# R7FA8D1BH register map
Vendor: Renesas; Series: RA8; File version: 1.2
CPU: CM85 r0p0, little endian, MPU, FPU, VTOR, 4 interrupt priority bits
Registers are 32-bit, read-write, reset 0x0 unless marked. A register's access mark holds for its fields unless they carry their own. Offsets are from the block's base; [hi:lo] are bit positions; {n}, {i} and the like mark numbered series; 'fields as' and 'values as' point back to an identical list.

## BUS — BUS Control
Base 0x40003000
Same registers: BUS_NS 0x50003000
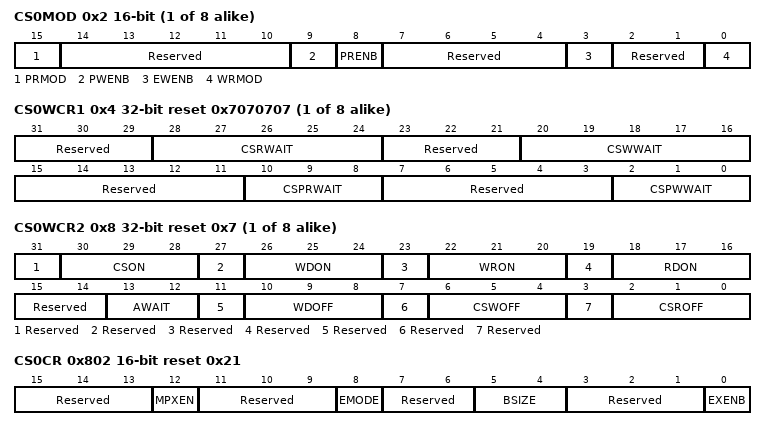
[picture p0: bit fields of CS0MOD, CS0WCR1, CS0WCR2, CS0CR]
{0x2+0x10*i} CS{i}MOD (i=0..7) 16-bit — CS{i} Mode Register
  [15] PRMOD — Page Read Access Mode Select
    0=Normal access compatible mode; 1=External data read continuous assertion mode
  [14:10] Reserved — These bits are read as 00000. The write value should be 00000.
  [9] PWENB — Page Write Access Enable
    0=Disabled; 1=Enabled
  [8] PRENB — Page Read Access Enable
    0=Disabled; 1=Enabled
  [7:4] Reserved — These bits are read as 0000. The write value should be 0000.
  [3] EWENB — External Wait Enable
    0=Disabled; 1=Enabled
  [2:1] Reserved — These bits are read as 00. The write value should be 00.
  [0] WRMOD — Write Access Mode Select
    0=Byte strobe mode; 1=Single write strobe mode
{0x4+0x10*i} CS{i}WCR1 (i=0..7) reset 0x7070707 — CS{i} Wait Control Register 1
  [31:29] Reserved — These bits are read as 000. The write value should be 000.
  [28:24] CSRWAIT — Normal Read Cycle Wait Select
    0=No wait is inserted; other=others (Wait with a length of CSRWAIT clock cycle is inserted.)
  [23:21] Reserved — These bits are read as 000. The write value should be 000.
  [20:16] CSWWAIT — Normal Write Cycle Wait Select
    0=No wait is inserted; other=others (Wait with a length of CSWWAIT clock cycle is inserted.)
  [15:11] Reserved — These bits are read as 00000. The write value should be 00000.
  [10:8] CSPRWAIT — Page Read Cycle Wait SelectNOTE: The CSPRWAIT value is valid only when the PRENB bit in CSnMOD is set to 1.
    0=No wait is inserted; other=others (Wait with a length of CSPRWAIT clock cycle is inserted.)
  [7:3] Reserved — These bits are read as 00000. The write value should be 00000.
  [2:0] CSPWWAIT — Page Write Cycle Wait SelectNOTE: The CSPWWAIT value is valid only when the PWENB bit in CSnMOD is set to 1.
    0=No wait is inserted; other=others (Wait with a length of CSPWWAIT clock cycle is inserted.)
{0x8+0x10*i} CS{i}WCR2 (i=0..7) reset 0x7 — CS{i} Wait Control Register 2
  [31] Reserved — This bit is read as 0. The write value should be 0.
  [30:28] CSON — CS Assert Wait Select
    0=No wait is inserted; other=others (Wait with a length of CSON clock cycle is inserted.)
  [27] Reserved — This bit is read as 0. The write value should be 0.
  [26:24] WDON — Write Data Output Wait Select
    0=No wait is inserted; other=others (Wait with a length of WDON clock cycle is inserted.)
  [23] Reserved — This bit is read as 0. The write value should be 0.
  [22:20] WRON — WR Assert Wait Select
    0=No wait is inserted; other=others (Wait with a length of WRON clock cycle is inserted.)
  [19] Reserved — This bit is read as 0. The write value should be 0.
  [18:16] RDON — RD Assert Wait Select
    0=No wait is inserted; other=others (Wait with a length of RDON clock cycle is inserted.)
  [15:14] Reserved — These bits are read as 00. The write value should be 00.
  [13:12] AWAIT — Address Cycle Wait Select
    0=No wait is inserted; other=others (Wait with a length of AWAIT clock cycle is inserted.)
  [11] Reserved — This bit is read as 0. The write value should be 0.
  [10:8] WDOFF — Write Data Output Extension Cycle Select
    0=No wait is inserted; other=others (Wait with a length of WDOFF clock cycle is inserted.)
  [7] Reserved — This bit is read as 0. The write value should be 0.
  [6:4] CSWOFF — Write Access CS Extension Cycle Select
    0=No wait is inserted; other=others (Wait with a length of CSWOFF clock cycle is inserted.)
  [3] Reserved — This bit is read as 0. The write value should be 0.
  [2:0] CSROFF — Read Access CS Extension Cycle Select
    0=No wait is inserted; other=others (Wait with a length of CSROFF clock cycle is inserted.)
0x802 CS0CR 16-bit reset 0x21 — CS0 Control Register
  [15:13] Reserved — These bits are read as 000. The write value should be 000.
  [12] MPXEN — Address/Data Multiplexed I/O Interface Select
    0=Separate bus interface is selected for area n; 1=Address/data multiplexed I/O interface is selected for area n. (n = 0 to 7)
  [11:9] Reserved — These bits are read as 000. The write value should be 000.
  [8] EMODE — Endian Mode
    0=Little endian; 1=Big endian
  [7:6] Reserved — These bits are read as 00. The write value should be 00.
  [5:4] BSIZE — External Bus Width Select
    0=16-bit bus space; 1=32-bit bus space; 2=8-bit bus space; other=others (Setting prohibited.)
  [3:1] Reserved — These bits are read as 000. The write value should be 000.
  [0] EXENB — Operation Enable
    0=Disable operation; 1=Enable operation
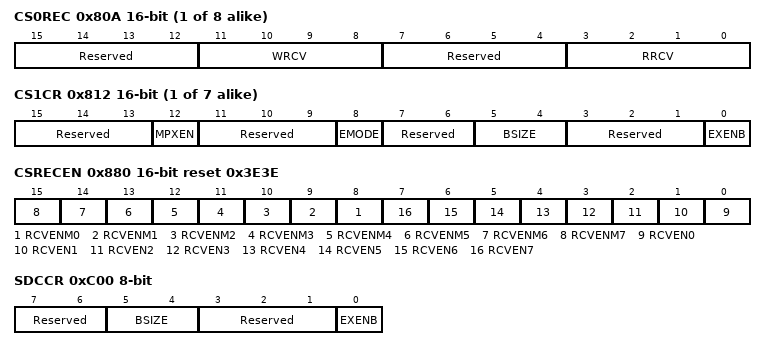
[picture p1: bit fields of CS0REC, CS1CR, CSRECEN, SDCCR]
{0x80A+0x10*i} CS{i}REC (i=0..7) 16-bit — CS{i} Recovery Cycle Register
  [15:12] Reserved — These bits are read as 0000. The write value should be 0000.
  [11:8] WRCV — Write Recovery
    0=No recovery cycle is inserted; other=others (WRCV recovery cycle is inserted.)
  [7:4] Reserved — These bits are read as 0000. The write value should be 0000.
  [3:0] RRCV — Read Recovery
    0=No recovery cycle is inserted; other=others (RRCV recovery cycle is inserted.)
{0x802+0x10*i} CS{i}CR (i=1..7) 16-bit — CS{i} Control Register
  fields as CS0CR
0x880 CSRECEN 16-bit reset 0x3E3E — CS Recovery Cycle Insertion Enable Register
  [all] fields
    0=Disabled; 1=Enabled
  [n+8] RCVENM{n} (n=0..7) — Multiplexed Bus Recovery Cycle Insertion Enable {n}
  [n] RCVEN{n} (n=0..7) — Separate Bus Recovery Cycle Insertion Enable {n}
0xC00 SDCCR 8-bit — SDC Control Register
  [7:6] Reserved — These bits are read as 00. The write value should be 00.
  [5:4] BSIZE — SDRAM Bus Width Select
    values as CS0CR.BSIZE
  [3:1] Reserved — These bits are read as 000. The write value should be 000.
  [0] EXENB — Operation Enable
    0=Disable; 1=Enable
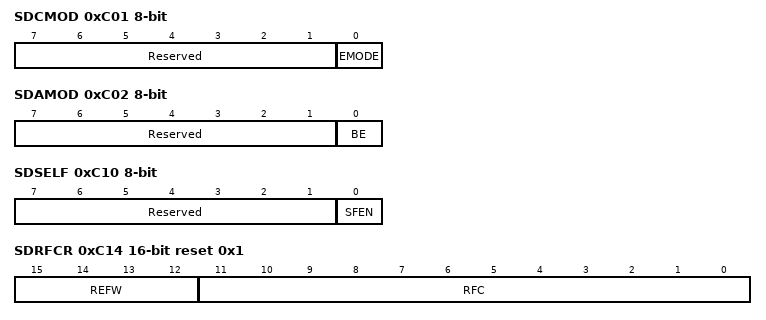
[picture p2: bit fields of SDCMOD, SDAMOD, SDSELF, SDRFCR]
0xC01 SDCMOD 8-bit — SDC Mode Register
  [7:1] Reserved — These bits are read as 0000000. The write value should be 0000000.
  [0] EMODE — Endian Mode
    0=Endian order of SDRAM address space is the same as the endian order of the operating mode; 1=Endian order of SDRAM address space is not the endian order of the operating mode
0xC02 SDAMOD 8-bit — SDRAM Access Mode Register
  [7:1] Reserved — These bits are read as 0000000. The write value should be 0000000.
  [0] BE — Continuous Access Enable
    0=Continuous access is disabled; 1=Continuous access is enabled
0xC10 SDSELF 8-bit — SDRAM Self-Refresh Control Register
  [7:1] Reserved — These bits are read as 0000000. The write value should be 0000000.
  [0] SFEN — SDRAM Self-Refresh Enable
    0=Disable; 1=Enable
0xC14 SDRFCR 16-bit reset 0x1 — SDRAM Refresh Control Register
  [15:12] REFW — Auto-Refresh Cycle/ Self-Refresh Clearing Cycle Count Setting. ( REFW+1 Cycles )
  [11:0] RFC — Auto-Refresh Request Interval Setting
    0=Setting prohibited; other=others (RFC+1 cycles inserted)
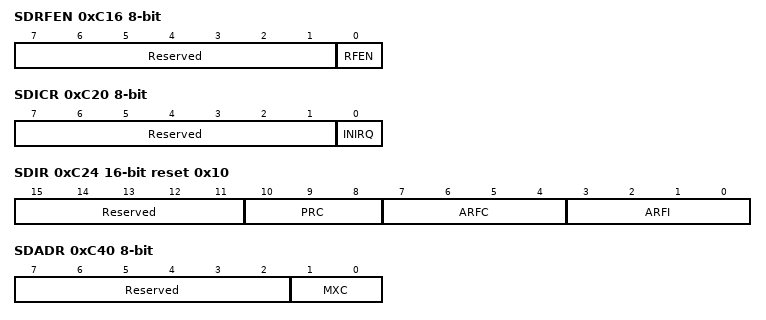
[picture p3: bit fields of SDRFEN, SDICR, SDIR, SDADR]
0xC16 SDRFEN 8-bit — SDRAM Auto-Refresh Control Register
  [7:1] Reserved — These bits are read as 0000000. The write value should be 0000000.
  [0] RFEN — Auto-Refresh Operation Enable
    0=Disable; 1=Enable
0xC20 SDICR 8-bit — SDRAM Initialization Sequence Control Register
  [7:1] Reserved — These bits are read as 0000000. The write value should be 0000000.
  [0] INIRQ — Initialization Sequence Start
    0=Invalid; 1=Initialization sequence starts
0xC24 SDIR 16-bit reset 0x10 — SDRAM Initialization Register
  [15:11] Reserved — These bits are read as 00000. The write value should be 00000.
  [10:8] PRC — Initialization Precharge Cycle Count ( PRF+3 cycles )
  [7:4] ARFC — Initialization Auto-Refresh Count
    0=Setting prohibited; other=others (ARFC+1 times)
  [3:0] ARFI — Initialization Auto-Refresh Interval ( PRF+3 cycles )
0xC40 SDADR 8-bit — SDRAM Address Register
  [7:2] Reserved — These bits are read as 000000. The write value should be 000000.
  [1:0] MXC — Address Multiplex Select
    {v}={v+8}-bit shift (v=0..3)
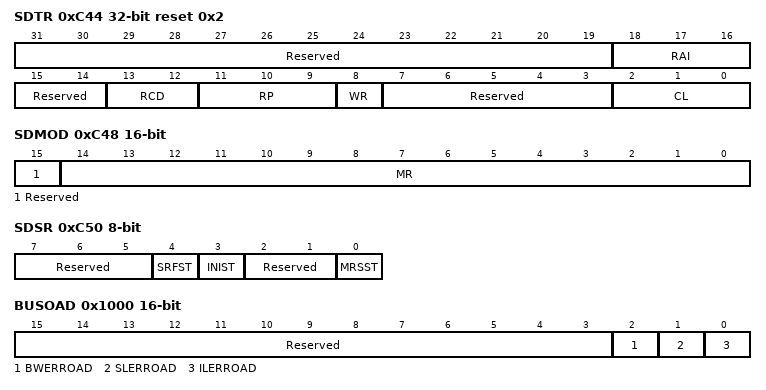
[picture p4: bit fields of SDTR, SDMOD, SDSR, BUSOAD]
0xC44 SDTR reset 0x2 — SDRAM Timing Register
  [31:19] Reserved — These bits are read as 0000000000000. The write value should be 0000000000000.
  [18:16] RAI — Row Active Interval
    0=1 cycle; {v}={v+1} cycles (v=1..6); 7=Setting prohibited
  [15:14] Reserved — These bits are read as 00. The write value should be 00.
  [13:12] RCD — Row Column Latency ( RCD+1 cycles )
  [11:9] RP — Row Precharge Interval ( RP+1 cycles )
  [8] WR — Write Recovery Interval
    0=1 cycle; 1=2 cycles
  [7:3] Reserved — These bits are read as 00000. The write value should be 00000.
  [2:0] CL — SDRAMC Column Latency
    1=1 cycle; 2=2 cycles; 3=3 cycles; other=others (Setting prohibited)
0xC48 SDMOD 16-bit — SDRAM Mode Register
  [15] Reserved — This bit is read as 0. The write value should be 0.
  [14:0] MR — Mode Register SettingWriting to these bits: Mode register set command is issued.
0xC50 SDSR 8-bit ro — SDRAM Status Register
  [7:5] Reserved — These bits are read as 000.
  [4] SRFST — Self-Refresh Transition/Recovery Status
    0=Transition/recovery not in progress; 1=Transition/recovery in progress
  [3] INIST — Initialization Status
    0=Initialization sequence not in progress; 1=Initialization sequence in progress
  [2:1] Reserved — These bits are read as 00.
  [0] MRSST — Mode Register Setting Status
    0=Mode register setting not in progress; 1=Mode register setting in progress
0x1000 BUSOAD 16-bit (reset mask 0x7) — BUS_Operation_After_Detection Register
  [15:3] Reserved — These bits are read as 0000000000000. The write value should be 0000000000000.
  [2] BWERROAD — Bufferable write error operation after detection
    0=NMI; 1=Reset
  [1] SLERROAD — Slave bus error operation after detection
    0=Only error response is returned; 1=Reset; 0=NMI; 1=Reset
  [0] ILERROAD — Illegal address access error operation after detection
    0=Only error response is returned; 1=Reset; 0=NMI; 1=Reset
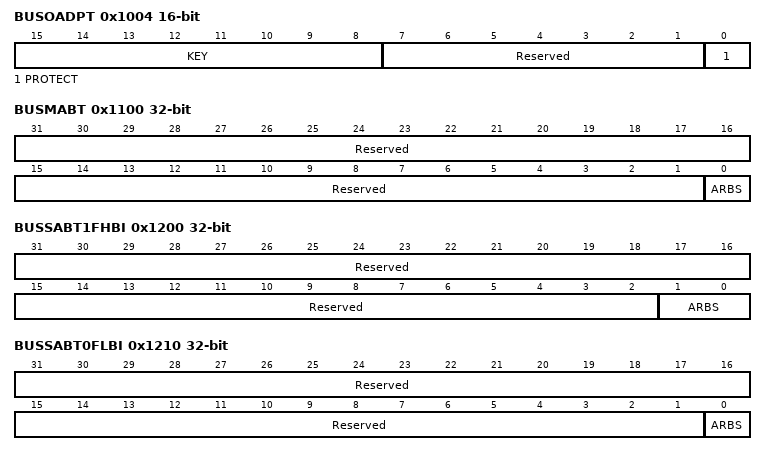
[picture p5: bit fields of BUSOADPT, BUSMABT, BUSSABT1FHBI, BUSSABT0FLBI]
0x1004 BUSOADPT 16-bit — BUS_Operation_After_Detection Protect Register
  [15:8] KEY wo — Key code
  [7:1] Reserved — These bits are read as 0000000. The write value should be 0000000.
  [0] PROTECT — Protection of register
    0=BUSOAD register writing is possible; 1=BUSOAD register writing is protected. Read is possible.
0x1100 BUSMABT — Bus Master Arbitration Control Register
  [31:16] Reserved — These bits are read as 0000000000000000. The write value should be 0000000000000000.
  [15:1] Reserved — These bits are read as 000000000000000. The write value should be 000000000000000.
  [0] ARBS — Arbitration Select
    0=Fixed priority; 1=Round-robin
0x1200 BUSSABT1FHBI — Bus Slave Arbitration Control Register 1 FHBI
  [31:16] Reserved — These bits are read as 0000000000000000. The write value should be 0000000000000000.
  [15:2] Reserved — These bits are read as 00000000000000. The write value should be 00000000000000.
  [1:0] ARBS — Arbitration Select
    0=Fixed priority; 1=Setting prohibited; 2=Combination of round-robin and fixed priority; 3=Round-robin
0x1210 BUSSABT0FLBI — Bus Slave Arbitration Control Register 0 FLBI
  fields as BUSMABT
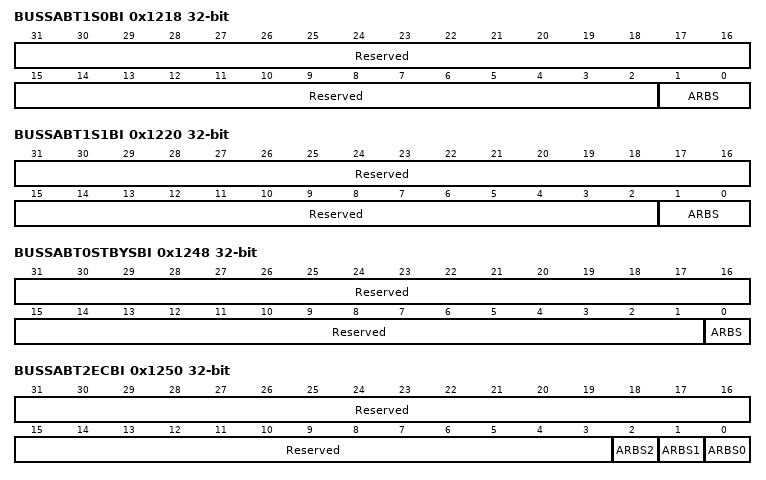
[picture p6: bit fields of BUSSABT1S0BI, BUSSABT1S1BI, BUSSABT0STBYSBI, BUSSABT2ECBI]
0x1218 BUSSABT1S0BI — Bus Slave Arbitration Control Register 1 S0BI
  fields as BUSSABT1FHBI
0x1220 BUSSABT1S1BI — Bus Slave Arbitration Control Register 1 S1BI
  fields as BUSSABT1FHBI
0x1248 BUSSABT0STBYSBI — Bus Slave Arbitration Control Register 0 STBYSBI
  fields as BUSMABT
0x1250 BUSSABT2ECBI — Bus Slave Arbitration Control Register 2 ECBI
  [31:16] Reserved — These bits are read as 0000000000000000. The write value should be 0000000000000000.
  [15:3] Reserved — These bits are read as 0000000000000. The write value should be 0000000000000.
  [2] ARBS2 — Arbitration Select
    0=Fixed priority; 1=Round-robin
  [1] ARBS1 — Arbitration Select
    0=Fixed priority; 1=Round-robin
  [0] ARBS0 — Arbitration Select
    0=Fixed priority; 1=Round-robin
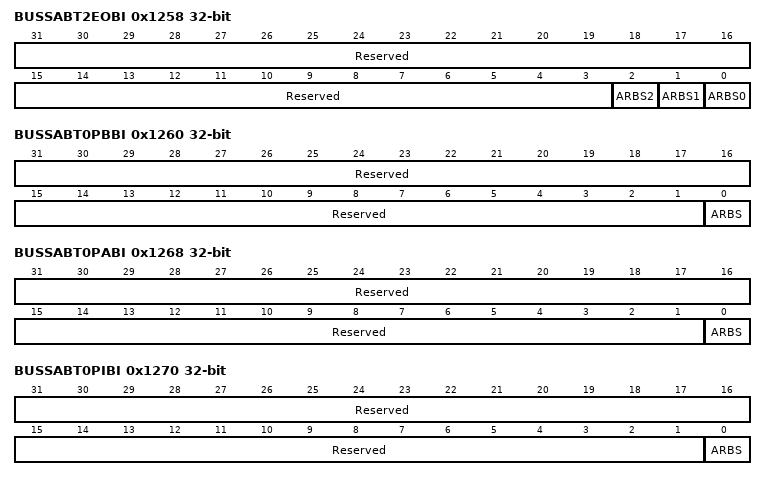
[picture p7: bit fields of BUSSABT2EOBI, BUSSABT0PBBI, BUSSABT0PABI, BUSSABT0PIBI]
0x1258 BUSSABT2EOBI — Bus Slave Arbitration Control Register 2 EOBI
  fields as BUSSABT2ECBI
0x1260 BUSSABT0PBBI — Bus Slave Arbitration Control Register 0 PBBI
  fields as BUSMABT
0x1268 BUSSABT0PABI — Bus Slave Arbitration Control Register 0 PABI
  fields as BUSMABT
0x1270 BUSSABT0PIBI — Bus Slave Arbitration Control Register 0 PIBI
  fields as BUSMABT
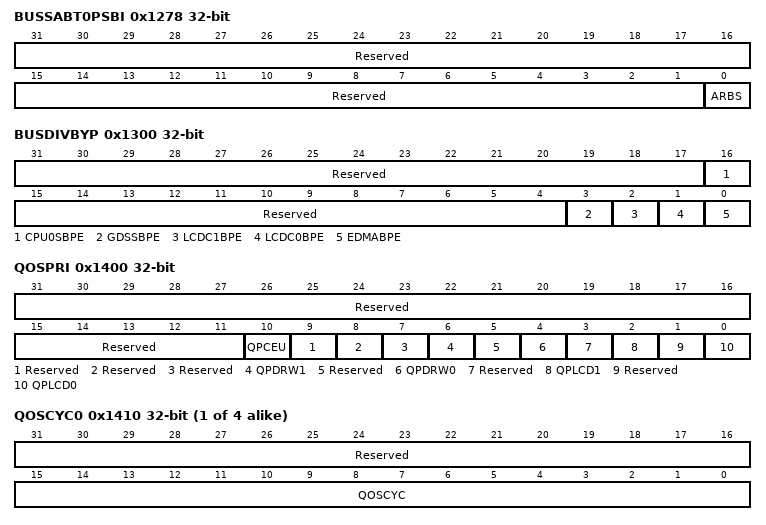
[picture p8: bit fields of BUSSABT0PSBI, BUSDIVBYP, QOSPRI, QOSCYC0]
0x1278 BUSSABT0PSBI — Bus Slave Arbitration Control Register 0 PSBI
  fields as BUSMABT
0x1300 BUSDIVBYP — Bus Divider Bypass Register
  [31:17] Reserved — These bits are read as 000000000000000. The write value should be 000000000000000.
  [16] CPU0SBPE — Divider for CPUSAHBI bypass enable
    0=Disable; 1=Enable
  [15:4] Reserved — These bits are read as 000000000000. The write value should be 000000000000.
  [3] GDSSBPE — Divider for GDSSBI bypass enable
    0=Disable; 1=Enable
  [2] LCDC1BPE — Divider for GLCDC1BI bypass enable
    0=Disable; 1=Enable
  [1] LCDC0BPE — Divider for GLCDC0BI bypass enable
    0=Disable; 1=Enable
  [0] EDMABPE — Divider for EDMACBI bypass enable
    0=Disable; 1=Enable
0x1400 QOSPRI — QoS Priority Setting After Reach Threshold
  [31:16] Reserved — These bits are read as 0000000000000000. The write value should be 0000000000000000.
  [15:11] Reserved — These bits are read as 00000. The write value should be 00000.
  [10] QPCEU
    0=Priority LOW; 1=Priority MIDDLE
  [9] Reserved — This bit is read as 0. The write value should be 0.
  [8] Reserved — This bit is read as 0. The write value should be 0.
  [7] Reserved — This bit is read as 0. The write value should be 0.
  [6] QPDRW1
    0=Priority LOW; 1=Priority MIDDLE
  [5] Reserved — This bit is read as 0. The write value should be 0.
  [4] QPDRW0
    0=Priority LOW; 1=Priority MIDDLE
  [3] Reserved — This bit is read as 0. The write value should be 0.
  [2] QPLCD1
    0=Priority LOW; 1=Priority MIDDLE
  [1] Reserved — This bit is read as 0. The write value should be 0.
  [0] QPLCD0
    0=Priority LOW; 1=Priority MIDDLE
{0x1410+8i} QOSCYC{i} (i=0..3) — QoS Cycle Setting Register {i}
  [31:16] Reserved — These bits are read as 0000000000000000. The write value should be 0000000000000000.
  [15:0] QOSCYC — QoS Unit Cycle Setting
    0=QoS circuit is disabled; 1=QoS unit cycle is 16; 2=QoS unit cycle is 32; 3=QoS unit cycle is 48; 0xFFFF=QoS unit cycle is 1,048,560
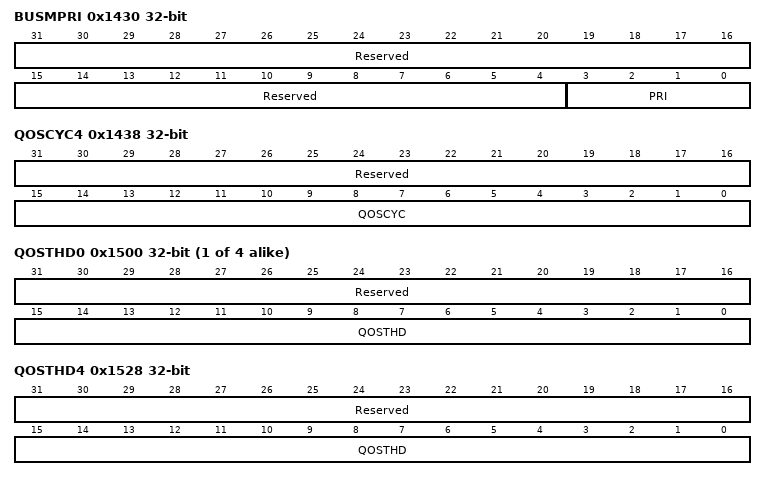
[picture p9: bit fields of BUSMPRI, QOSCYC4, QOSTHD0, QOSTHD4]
0x1430 BUSMPRI — Bus Master priority setting register
  [31:16] Reserved — These bits are read as 0000000000000000. The write value should be 0000000000000000.
  [15:4] Reserved — These bits are read as 000000000000. The write value should be 000000000000.
  [3:0] PRI — Priority Select
    0=Priority of MIPI is MIDDLE; 15=Priority of MIPI is LOW
0x1438 QOSCYC4 — QoS Cycle Setting Register 4
  fields as QOSCYC0
{0x1500+8i} QOSTHD{i} (i=0..3) — QoS Threshold Setting Register {i}
  [31:16] Reserved — These bits are read as 0000000000000000. The write value should be 0000000000000000.
  [15:0] QOSTHD — QoS Threshold Setting
    0=Threshold is 0 byte; 1=Threshold is 1 byte; 2=Threshold is 2 bytes; 3=Threshold is 3 bytes; 0xFFFF=Threshold is 65,535 bytes
0x1528 QOSTHD4 — QoS Threshold Setting Register 4
  fields as QOSTHD0
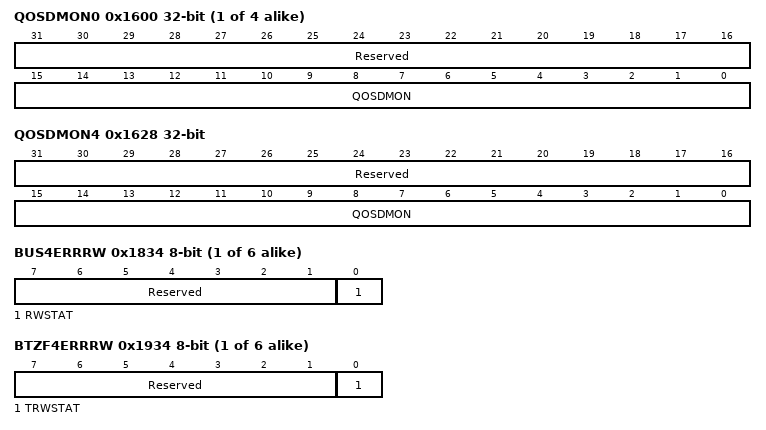
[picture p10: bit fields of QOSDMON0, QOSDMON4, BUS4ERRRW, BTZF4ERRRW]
{0x1600+8i} QOSDMON{i} (i=0..3) — QoS Data Transferred Amount Monitor Register {i}
  [31:16] Reserved — These bits are read as 0000000000000000. The write value should be 0000000000000000.
  [15:0] QOSDMON — QoS data transferred amount within a unit cycle
    0=0 byte; 1=1 byte; 2=2 bytes; 3=3 bytes; 0xFFFF=65,535 or more bytes
0x1628 QOSDMON4 — QoS Data Transferred Amount Monitor Register 4
  fields as QOSDMON0
{0x17F0+0x10*i} BUS{i}ERRADD (i=4..9) ro reset not defined — Bus Error Address Register {i}
  [31:0] BERAD — Bus Error AddressWhen a bus error occurs, It stores an error address.
{0x17F4+0x10*i} BUS{i}ERRRW (i=4..9) 8-bit ro (reset mask 0x1) — Bus Error RW Register {i}
  [7:1] Reserved — These bits are read as 0000000.
  [0] RWSTAT — error access Read/Write STAtus
    0=Read access; 1=Write access
{0x18F0+0x10*i} BTZF{i}ERRADD (i=4..9) ro reset not defined — Bus TZF Error Address Register {i}
  [31:0] BTZFERAD — Bus TZF Error Adress When a TZF error occurs, It stores an error address.
{0x18F4+0x10*i} BTZF{i}ERRRW (i=4..9) 8-bit ro (reset mask 0x1) — Bus ZTF Error RW Register {i}
  [7:1] Reserved — These bits are read as 0000000.
  [0] TRWSTAT — TrustZone filter error access Read/Write STAtus
    0=Read access; 1=Write access
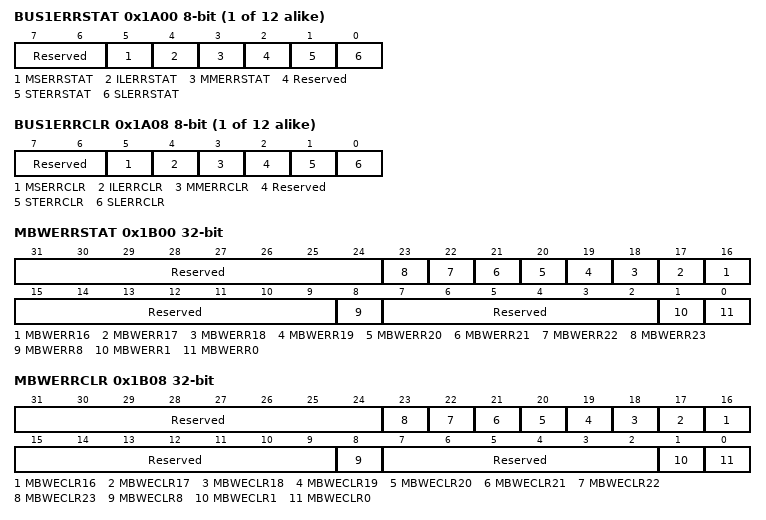
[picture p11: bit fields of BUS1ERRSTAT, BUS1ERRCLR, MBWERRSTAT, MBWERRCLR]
{0x19F0+0x10*i} BUS{i}ERRSTAT (i=1..12) 8-bit ro (reset mask 0x3F) — Bus Error Status Register {i}
  [7:6] Reserved — These bits are read as 00.
  [5] MSERRSTAT — Master Security attribution unit ERRor STATus
    0=No error occurred; 1=Error occurred
  [4] ILERRSTAT — Illegal address access ERRor STATus
    0=No error occurred; 1=Error occurred
  [3] MMERRSTAT — Master MPU ERRor STATus
    0=No error occurred; 1=Error occurred
  [2] Reserved — This bit is read as 0.
  [1] STERRSTAT — Slave TrustZone filter ERRor STATus
    0=No error occurred; 1=Error occurred
  [0] SLERRSTAT — Slave bus ERRor STATus
    0=No error occurred; 1=Error occurred
{0x19F8+0x10*i} BUS{i}ERRCLR (i=1..12) 8-bit (reset mask 0x3F) — Bus Error Status Register {i}
  [7:6] Reserved — These bits are read as 00. The write value should be 00.
  [5] MSERRCLR — Master Security attribution unit ERRor CleaR
  [4] ILERRCLR — Illegal address access ERRor CleaR
  [3] MMERRCLR — Master MPU ERRor CleaR
  [2] Reserved — This bit is read as 0. The write value should be 0.
  [1] STERRCLR — Slave TrustZone filter ERRor CleaR
  [0] SLERRCLR — Slave bus ERRor CleaR
0x1B00 MBWERRSTAT ro — Master Bufferable Write Error Status Register
  [31:24] Reserved — These bits are read as 00000000.
  [n] MBWERR{n} (n=16..23) — Master Bufferable Write Error
    0=No bufferable write error in Master #{n}; 1=Bufferable write error occurs in Master #{n}
  [15:9] Reserved — These bits are read as 0000000.
  [8] MBWERR8 — Master Bufferable Write Error
    0=No bufferable write error in Master #8; 1=Bufferable write error occurs in Master #8
  [7:2] Reserved — These bits are read as 000000.
  [1] MBWERR1 — Master Bufferable Write Error
    0=No bufferable write error in Master #1; 1=Bufferable write error occurs in Master #1
  [0] MBWERR0 — Master Bufferable Write Error
    0=No bufferable write error in Master #0; 1=Bufferable write error occurs in Master #0
0x1B08 MBWERRCLR — Master Bufferable Write Error Clear Register
  [31:24] Reserved — These bits are read as 00000000. The write value should be 00000000.
  [n] MBWECLR{n} (n=16..23) — Master Bufferable Write Error Clear
  [15:9] Reserved — These bits are read as 0000000. The write value should be 0000000.
  [8] MBWECLR8 — Master Bufferable Write Error Clear
  [7:2] Reserved — These bits are read as 000000. The write value should be 000000.
  [1] MBWECLR1 — Master Bufferable Write Error Clear
  [0] MBWECLR0 — Master Bufferable Write Error Clear
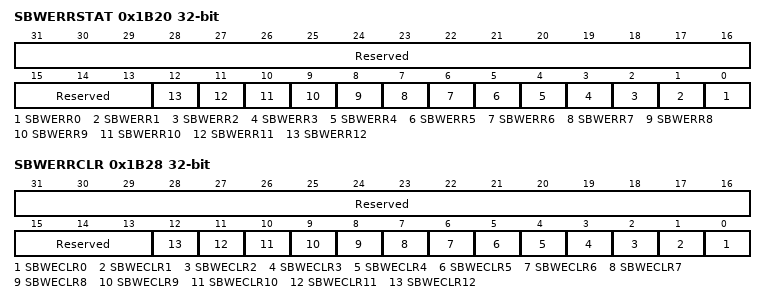
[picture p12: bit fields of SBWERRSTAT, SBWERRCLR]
0x1B20 SBWERRSTAT ro — Slave Bufferable Write Error Status Register
  [31:16] Reserved — These bits are read as 0000000000000000.
  [15:13] Reserved — These bits are read as 000.
  [n] SBWERR{n} (n=0..12) — Slave Bufferable Write Error
    0=No bufferable write error in Slave #{n}; 1=Bufferable write error occurs in Slave #{n}
0x1B28 SBWERRCLR — Slave Bufferable Write Error Clear Register
  [31:16] Reserved — These bits are read as 0000000000000000. The write value should be 0000000000000000.
  [15:13] Reserved — These bits are read as 000. The write value should be 000.
  [n] SBWECLR{n} (n=0..12) — Slave Bufferable Write Error Clear
